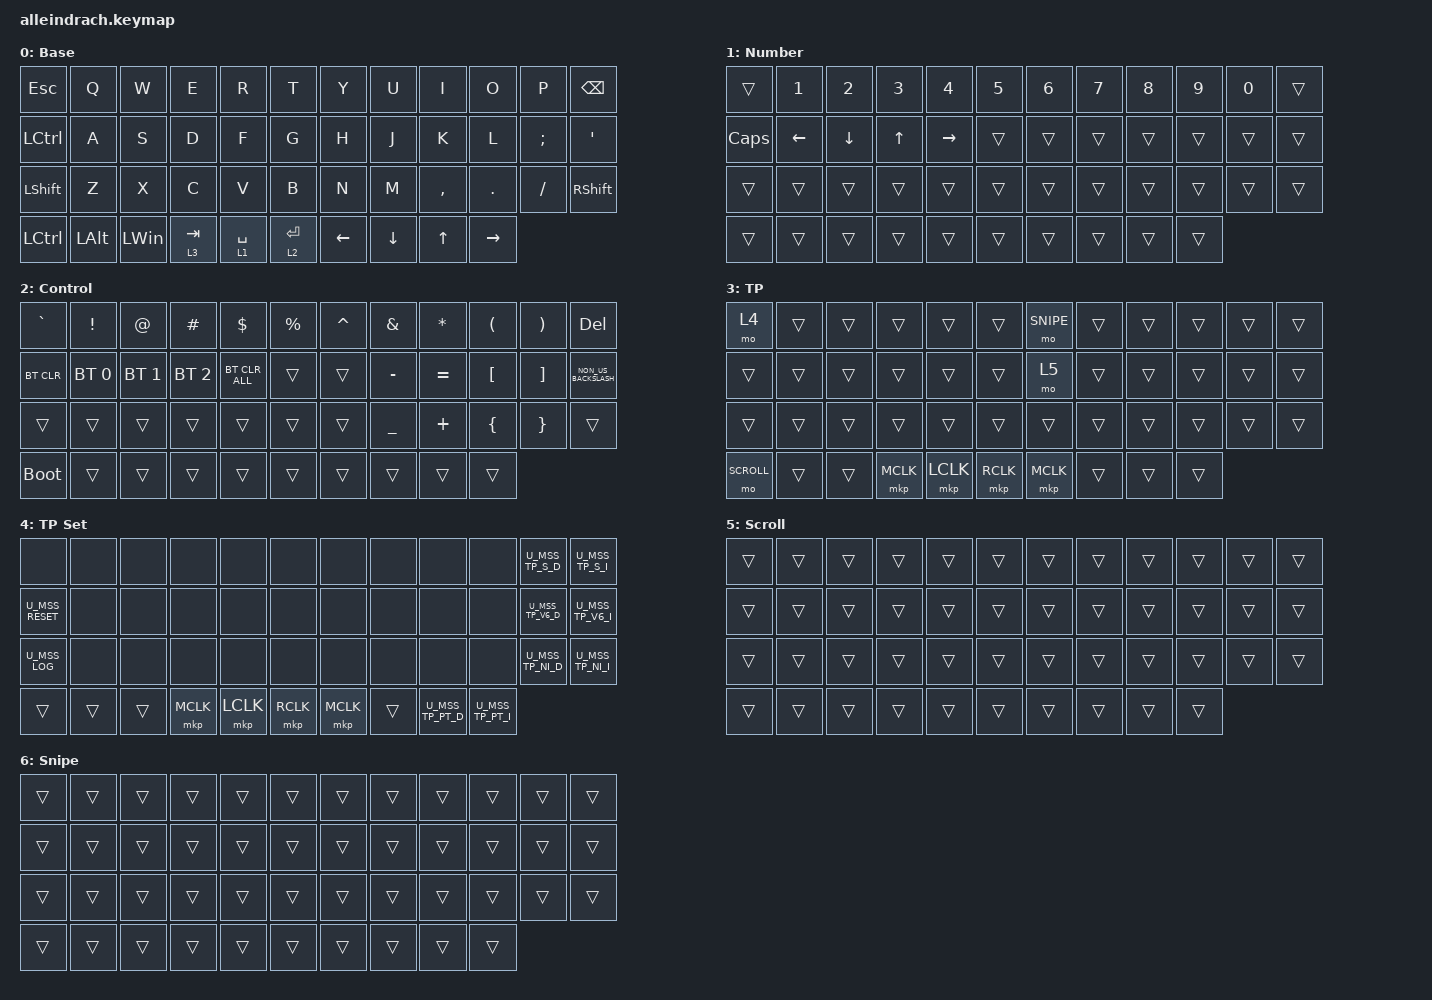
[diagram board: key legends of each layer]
/*
 * Copyright (c) 2020 The ZMK Contributors
 *
 * SPDX-License-Identifier: MIT
 */

#include <dt-bindings/zmk/indicator.h>

// Mainline ZMK's `behaviors.dtsi` does not pull in the RGB status-indicator
// behaviour; the zmk-ps2 fork added the include to its own copy of that file.
// Here the behaviour ships with this repo's local module instead, so it has to
// be included explicitly. See zephyr/module.yml (dts_root) and
// dts/behaviors/rgb_indicators.dtsi.

#include <behaviors/rgb_indicators.dtsi>

#define BASE 0
#define LOWER 1
#define RAISE 2
#define DEFAULT_LAYER 0
#define NUM_LAYER 1
#define CONTROL_LAYER 2
#define MOUSE_TP 3
#define MOUSE_TP_SET 4

// Scroll mode layer. Holding `&mo SCROLL` makes the TrackPoint listener report
// wheel/horizontal-wheel instead of pointer movement -- see
// `include/mouse_tp.dtsi`. This replaced the fork's `&mmm` behaviour.

#define SCROLL 5

// Precision ("snipe") layer. Holding `&mo SNIPE` makes the TrackPoint listener
// scale stick movement down to 1/4 speed for fine positioning -- see the
// `snipe` override in `include/mouse_tp.dtsi`.
//
// Appended AFTER `SCROLL` on purpose: layer indices are node order, so adding
// it at the end leaves 0..5 untouched.

#define SNIPE 6

/*
 * Defines to enable/disable features
 *
 * These defines allow us to conditionally enable and disable parts of the keymap config.
 *
 * For example, if we decide to build the firmware without the mouse features, we can
 * disable all the config options that rely on those forks and modules without having
 * to edit the entire keymap file manually every time.
 */

#include <behaviors/mouse_keys.dtsi>

// TEMP(migration): `behaviors/mouse_mode.dtsi` (the `&mmm` behaviour) lived in
// alleindrach's own PS/2 driver module fork; it is being ported back too.
// #include <behaviors/mouse_mode.dtsi>

#define HAS_MOUSE_KEYS
  #define HAS_MOUSE_TP

#include "include/mouse_tp.dtsi"
#include <dt-bindings/zmk/mouse.h>
#include <behaviors.dtsi>
#include <dt-bindings/zmk/bt.h>
#include <dt-bindings/zmk/keys.h>
#include <dt-bindings/zmk/pointing.h>

#define U_TOG_TP_SET &mo MOUSE_TP_SET

/ {
    behaviors {
        mo_ctrl_or_tp: mo_ctrl_or_tp {
            compatible = "zmk,behavior-mod-morph";
            #binding-cells = <0>;
            bindings = <&mo CONTROL_LAYER>, <&mo MOUSE_TP_SET>;

            mods = <(MOD_LCTL)>;
        };

        semi_bracket: semi_bracket {
            compatible = "zmk,behavior-mod-morph";
            #binding-cells = <0>;
            bindings = <&kp SEMI>, <&kp LEFT_BRACKET>;

            mods = <(MOD_LCTL|MOD_LGUI)>;
        };

        quot_bracket: quot_bracket {
            compatible = "zmk,behavior-mod-morph";
            #binding-cells = <0>;
            bindings = <&kp SINGLE_QUOTE>, <&kp RIGHT_BRACKET>;

            mods = <(MOD_LCTL|MOD_LGUI)>;
        };

        td_spc_num: tap_dance_space_or_number_layer {
            compatible = "zmk,behavior-tap-dance";
            #binding-cells = <0>;
            tapping-term-ms = <200>;
            bindings = <&kp SPACE>, <&to NUM_LAYER>;
        };

        td_spc_dft: tap_dance_space_or_default_layer {
            compatible = "zmk,behavior-tap-dance";
            #binding-cells = <0>;
            tapping-term-ms = <200>;
            bindings = <&kp SPACE>, <&to DEFAULT_LAYER>;
        };

        td_rarr_end: td_rarr_end {
            compatible = "zmk,behavior-tap-dance";
            #binding-cells = <0>;
            tapping-term-ms = <150>;
            bindings = <&kp RIGHT_ARROW>, <&kp END>;
        };

        td_larr_home: td_larr_home {
            compatible = "zmk,behavior-tap-dance";
            #binding-cells = <0>;
            tapping-term-ms = <150>;
            bindings = <&kp LEFT_ARROW>, <&kp HOME>;
        };

        mod_rgui_Q_1: mod_rgui_Q_1 {
            compatible = "zmk,behavior-mod-morph";
            #binding-cells = <0>;
            bindings = <&kp Q>, <&kp N1>;

            mods = <(MOD_RGUI)>;
        };

        mod_rgui_W_2: mod_rgui_W_2 {
            compatible = "zmk,behavior-mod-morph";
            #binding-cells = <0>;
            bindings = <&kp W>, <&kp N2>;

            mods = <(MOD_RGUI)>;
        };

        mod_rgui_E_3: mod_rgui_E_3 {
            compatible = "zmk,behavior-mod-morph";
            #binding-cells = <0>;
            bindings = <&kp E>, <&kp N3>;

            mods = <(MOD_RGUI)>;
        };

        mod_rgui_R_4: mod_rgui_R_4 {
            compatible = "zmk,behavior-mod-morph";
            #binding-cells = <0>;
            bindings = <&kp R>, <&kp N4>;

            mods = <(MOD_RGUI)>;
        };

        mod_rgui_T_5: mod_rgui_T_5 {
            compatible = "zmk,behavior-mod-morph";
            #binding-cells = <0>;
            bindings = <&kp T>, <&kp N5>;

            mods = <(MOD_RGUI)>;
        };

        mod_rgui_Y_6: mod_rgui_Y_6 {
            compatible = "zmk,behavior-mod-morph";
            #binding-cells = <0>;
            bindings = <&kp Y>, <&kp N6>;

            mods = <(MOD_RGUI)>;
        };

        mod_rgui_U_7: mod_rgui_U_7 {
            compatible = "zmk,behavior-mod-morph";
            #binding-cells = <0>;
            bindings = <&kp U>, <&kp N7>;

            mods = <(MOD_RGUI)>;
        };

        mod_rgui_I_8: mod_rgui_I_8 {
            compatible = "zmk,behavior-mod-morph";
            #binding-cells = <0>;
            bindings = <&kp I>, <&kp N8>;

            mods = <(MOD_RGUI)>;
        };

        mod_rgui_O_9: mod_rgui_O_9 {
            compatible = "zmk,behavior-mod-morph";
            #binding-cells = <0>;
            bindings = <&kp O>, <&kp N9>;

            mods = <(MOD_RGUI)>;
        };

        mod_rgui_P_0: mod_rgui_P_0 {
            compatible = "zmk,behavior-mod-morph";
            #binding-cells = <0>;
            bindings = <&kp P>, <&kp N0>;

            mods = <(MOD_RGUI)>;
        };

        mod_rgui_M_1: mod_rgui_M_1 {
            compatible = "zmk,behavior-mod-morph";
            #binding-cells = <0>;
            bindings = <&kp M>, <&kp N1>;

            mods = <(MOD_RGUI)>;
        };

        mod_rgui_COMMA_2: mod_rgui_COMMA_2 {
            compatible = "zmk,behavior-mod-morph";
            #binding-cells = <0>;
            bindings = <&kp COMMA>, <&kp N2>;

            mods = <(MOD_RGUI)>;
        };

        mod_rgui_DOT_3: mod_rgui_DOT_3 {
            compatible = "zmk,behavior-mod-morph";
            #binding-cells = <0>;
            bindings = <&kp DOT>, <&kp N3>;

            mods = <(MOD_RGUI)>;
        };

        mod_rgui_J_4: mod_rgui_J_4 {
            compatible = "zmk,behavior-mod-morph";
            #binding-cells = <0>;
            bindings = <&kp J>, <&kp N4>;

            mods = <(MOD_RGUI)>;
        };

        mod_rgui_K_5: mod_rgui_K_5 {
            compatible = "zmk,behavior-mod-morph";
            #binding-cells = <0>;
            bindings = <&kp K>, <&kp N5>;

            mods = <(MOD_RGUI)>;
        };

        mod_rgui_L_6: mod_rgui_L_6 {
            compatible = "zmk,behavior-mod-morph";
            #binding-cells = <0>;
            bindings = <&kp L>, <&kp N6>;

            mods = <(MOD_RGUI)>;
        };

        mod_lshft_larr_home: mod_lshft_larr_home {
            compatible = "zmk,behavior-mod-morph";
            #binding-cells = <0>;
            bindings = <&kp LEFT_ARROW>, <&kp HOME>;

            mods = <(MOD_LSFT)>;
        };

        mod_lshft_rarr_end: mod_lshft_rarr_end {
            compatible = "zmk,behavior-mod-morph";
            #binding-cells = <0>;
            bindings = <&kp RIGHT_ARROW>, <&kp END>;

            mods = <(MOD_LSFT)>;
        };

        mod_lgui_bksp_del: mod_lshft_bksp_del {
            compatible = "zmk,behavior-mod-morph";
            #binding-cells = <0>;
            bindings = <&kp BACKSPACE>, <&kp DEL>;

            mods = <(MOD_LGUI)>;
        };

        mod_lshft_uarr_pgup: mod_lshft_uarr_pgup {
            compatible = "zmk,behavior-mod-morph";
            #binding-cells = <0>;
            bindings = <&kp UP_ARROW>, <&kp PG_UP>;

            mods = <(MOD_LSFT)>;
        };

        mod_lshft_darr_pgdn: mod_lshft_darr_pgdn {
            compatible = "zmk,behavior-mod-morph";
            #binding-cells = <0>;
            bindings = <&kp DOWN_ARROW>, <&kp PG_DN>;

            mods = <(MOD_LSFT)>;
        };
    };

    keymap {
        compatible = "zmk,keymap";

        default_layer {
            display-name = "Base";
            bindings = <
&kp ESC    &kp Q         &kp W         &kp E      &kp R        &kp T        &kp Y     &kp U     &kp I      &kp O      &kp P      &kp BACKSPACE
&kp LCTRL  &kp A         &kp S         &kp D      &kp F        &kp G        &kp H     &kp J     &kp K      &kp L      &kp SEMI   &kp SQT
&kp LSHFT  &kp Z         &kp X         &kp C      &kp V        &kp B        &kp N     &kp M     &kp COMMA  &kp DOT    &kp SLASH  &kp RSHFT
&kp LCTRL  &kp LEFT_ALT  &kp LEFT_WIN  &lt 3 TAB  &lt 1 SPACE  &lt 2 ENTER  &kp LEFT  &kp DOWN  &kp UP     &kp RIGHT
            >;
        };

        number_layer {
            display-name = "Number";
            bindings = <
&trans    &kp N1    &kp N2    &kp N3  &kp N4     &kp N5  &kp N6  &kp N7  &kp N8  &kp N9  &kp N0  &trans
&kp CAPS  &kp LEFT  &kp DOWN  &kp UP  &kp RIGHT  &trans  &trans  &trans  &trans  &trans  &trans  &trans
&trans    &trans    &trans    &trans  &trans     &trans  &trans  &trans  &trans  &trans  &trans  &trans
&trans    &trans    &trans    &trans  &trans     &trans  &trans  &trans  &trans  &trans
            >;
        };

        control_layer {
            display-name = "Control";
            bindings = <
&kp GRAVE    &kp EXCL      &kp AT        &kp POUND     &kp DLLR        &kp PRCNT  &kp CARET  &kp AMPS   &kp ASTRK  &kp LPAR  &kp RPAR  &kp DELETE
&bt BT_CLR   &bt BT_SEL 0  &bt BT_SEL 1  &bt BT_SEL 2  &bt BT_CLR_ALL  &trans     &trans     &kp MINUS  &kp EQUAL  &kp LBKT  &kp RBKT  &kp NON_US_BACKSLASH
&trans       &trans        &trans        &trans        &trans          &trans     &trans     &kp UNDER  &kp PLUS   &kp LBRC  &kp RBRC  &trans
&bootloader  &trans        &trans        &trans        &trans          &trans     &trans     &trans     &trans     &trans
            >;
        };

        // Automatically activated when the mouse or trackpoint moves.
        // Configured in `include/mouse_tp.dtsi`.
        //
        // `&mo SCROLL` replaces the fork's `&mmm` (mouse move/scroll mode toggle)
        // at the same two positions it used to occupy: the 7th key of the top row
        // and the first key of the bottom row. Hold either one and move the
        // TrackPoint to scroll. Since the TP layer is only up while the stick
        // moves (150ms timeout), hold `&lt 3 TAB` on the base layer first if you
        // want to scroll without touching the stick to wake the layer.

        MouseTP_layer {
            display-name = "TP";
            bindings = <
&mo 4       &trans  &trans  &trans     &trans     &trans     &mo SNIPE  &trans  &trans  &trans  &trans  &trans
&trans      &trans  &trans  &trans     &trans     &trans     &mo 5      &trans  &trans  &trans  &trans  &trans
&trans      &trans  &trans  &trans     &trans     &trans     &trans     &trans  &trans  &trans  &trans  &trans
&mo SCROLL  &trans  &trans  &mkp MCLK  &mkp LCLK  &mkp RCLK  &mkp MCLK  &trans  &trans  &trans
            >;
        };

        // You can find the defines for the actual key press behaviors in `include/mouse_tp.dtsi`.

        MouseSettings_layer {
            display-name = "TP Set";

            // Upstream shipped `U_MSS_TP_V6_D` twice on the second row, so the
            // "raise the upper plateau speed" key was a no-op duplicate of the
            // lower one. The second entry is the increase key.

            bindings = <
&none  &none  &none  &none                              &none   &none   &none                                        &none      &none      &none U_MSS_TP_S_D U_MSS_TP_S_I U_MSS_RESET  &none      &none
&none  &none  &none  &none                              &none   &none   &none U_MSS_TP_V6_D U_MSS_TP_V6_I U_MSS_LOG  &none      &none      &none                                        &none      &none
&none  &none  &none  &none U_MSS_TP_NI_D U_MSS_TP_NI_I  &trans  &trans  &trans                                       &mkp MCLK  &mkp LCLK  &mkp RCLK                                    &mkp MCLK  &trans U_MSS_TP_PT_D U_MSS_TP_PT_I
            >;
        };

        // MUST stay after `MouseSettings_layer`: `SCROLL` and `SNIPE` are
        // `#define`d to indices 5 and 6, and inserting a layer before the TP Set
        // layer would shift `MOUSE_TP_SET` (4) out from under its entry key.
        //
        // Held down by `&mo SCROLL` on the TP layer. Every key stays transparent,
        // so this layer only exists to flip the TrackPoint into scroll mode.

        Scroll_layer {
            display-name = "Scroll";
            bindings = <
&trans  &trans  &trans  &trans  &trans  &trans  &trans  &trans  &trans  &trans  &trans  &trans
&trans  &trans  &trans  &trans  &trans  &trans  &trans  &trans  &trans  &trans  &trans  &trans
&trans  &trans  &trans  &trans  &trans  &trans  &trans  &trans  &trans  &trans  &trans  &trans
&trans  &trans  &trans  &trans  &trans  &trans  &trans  &trans  &trans  &trans
            >;
        };

        // Precision layer. Held down by `&mo SNIPE` on the TP layer (the key that
        // sits on the base layer's `Y` position). Every key stays transparent --
        // the layer carries no bindings of its own, it only tells the TrackPoint
        // listener to slow the stick down to 1/4 speed. See the `snipe` override
        // in `include/mouse_tp.dtsi`.

        Snipe_layer {
            display-name = "Snipe";
            bindings = <
&trans  &trans  &trans  &trans  &trans  &trans  &trans  &trans  &trans  &trans  &trans  &trans
&trans  &trans  &trans  &trans  &trans  &trans  &trans  &trans  &trans  &trans  &trans  &trans
&trans  &trans  &trans  &trans  &trans  &trans  &trans  &trans  &trans  &trans  &trans  &trans
&trans  &trans  &trans  &trans  &trans  &trans  &trans  &trans  &trans  &trans
            >;
        };
    };
};
